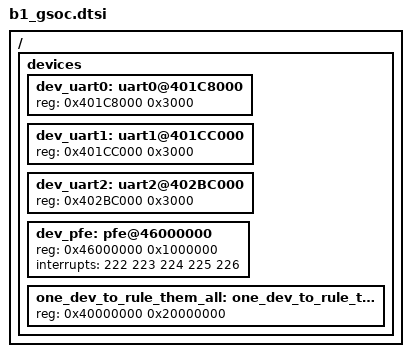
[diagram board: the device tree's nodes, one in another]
/*
 * Copyright (c) 2023-2024, ProvenRun and/or its affiliates.
 * All rights reserved.
 *
 * This software is the confidential and proprietary information of
 * ProvenRun S.A.S ("Confidential Information"). You shall not
 * disclose such Confidential Information and shall use it only in
 * accordance with the terms of the license agreement you entered
 * into with ProvenRun S.A.S
 *
 * PROVENRUN S.A.S MAKES NO REPRESENTATIONS OR WARRANTIES ABOUT THE
 * SUITABILITY OF THE SOFTWARE, EITHER EXPRESS OR IMPLIED, INCLUDING
 * BUT NOT LIMITED TO THE IMPLIED WARRANTIES OF MERCHANTABILITY, FITNESS
 * FOR A PARTICULAR PURPOSE, OR NON-INFRINGEMENT. PROVE & RUN S.A.S SHALL
 * NOT BE LIABLE FOR ANY DAMAGES SUFFERED BY LICENSEE AS A RESULT OF USING,
 * MODIFYING OR DISTRIBUTING THIS SOFTWARE OR ITS DERIVATIVES.
 */
/**
 * @file    : b1_gsoc.dtsi
 * @brief   : SoC level definition
 *
 * @author  : Aymeric PLOTON aymeric.ploton@provenrun.com
 * @date    : 23/02/2024 (creation)
 * Copyright (c) 2023-2024, ProvenRun and/or its affiliates.
 * All rights reserved.
 */

#include "plat_common.dtsi"

/ {
	devices {
		#address-cells = <1>;
		#size-cells    = <1>;

		dev_uart0: uart0@401C8000 {		// BASEADDR is the base address of the uart0 device, without prefix "0x"
			reg = <0x401C8000 0x3000>;	// This information should be found in the reference manual : RMS32G3.pdf
		};

		dev_uart1: uart1@401CC000 {		// BASEADDR is the base address of the uart1 device, without prefix "0x"
			reg = <0x401CC000 0x3000>;	// This information should be found in the reference manual : RMS32G3.pdf
		};

		dev_uart2: uart2@402BC000 {		// BASEADDR is the base address of the uart2 device, without prefix "0x"
			reg = <0x402BC000 0x3000>;	// This information should be found in the reference manual : RMS32G3.pdf
		};
		
		dev_pfe: pfe@46000000 {		        // BASEADDR is the base address of the pfe device, without prefix "0x"
			reg = <0x46000000 0x1000000>;	// This information should be found in the reference manual : RMS32G3.pdf
			interrupts = <222 223 224 225 226>;
			interrupt-names = "PFE_CHAN0", "PFE_CHAN1", "PFE_CHAN2", "PFE_CHAN3", "PFE_BMU";
		};

		one_dev_to_rule_them_all: one_dev_to_rule_them_all@40000000 {
			reg = <0x40000000 0x20000000>;
		};

	};
  };
